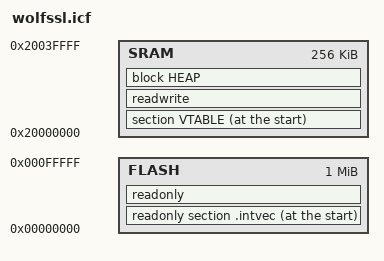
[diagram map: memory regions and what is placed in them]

define memory mem with size = 4G;
define region FLASH = mem:[from 0x00000000 to 0x000fffff];
define region SRAM = mem:[from 0x20000000 to 0x2003ffff];
define block HEAP with alignment = 8, size = 0x00010000 { };
initialize by copy { readwrite };
do not initialize { section .noinit };
place at start of FLASH { readonly section .intvec };
place in FLASH { readonly };
place at start of SRAM { section VTABLE };
place in SRAM { readwrite, block HEAP };
